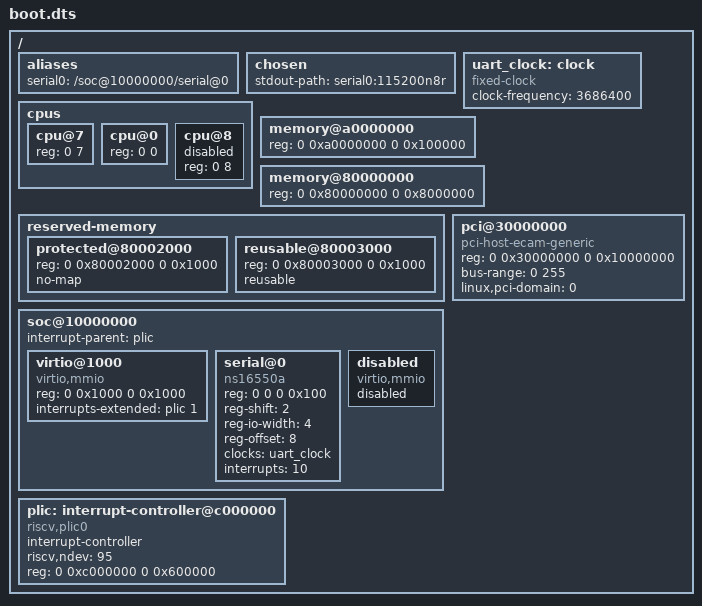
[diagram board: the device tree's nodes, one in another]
// SPDX-License-Identifier: MPL-2.0

/dts-v1/;
/memreserve/ 0x80000000 0x2000;

/ {
    #address-cells = <2>;
    #size-cells = <2>;

    aliases { serial0 = "/soc@10000000/serial@0"; };
    chosen { stdout-path = "serial0:115200n8r"; };
    uart_clock: clock { compatible = "fixed-clock"; #clock-cells = <0>; clock-frequency = <3686400>; };
    cpus {
        #address-cells = <2>;
        #size-cells = <0>;
        cpu@7 { device_type = "cpu"; reg = <0 7>; };
        cpu@0 { device_type = "cpu"; reg = <0 0>; };
        cpu@8 { device_type = "cpu"; reg = <0 8>; status = "disabled"; };
    };
    memory@a0000000 {
        device_type = "memory";
        reg = <0 0xa0000000 0 0x100000>;
    };
    memory@80000000 {
        device_type = "memory";
        reg = <0 0x80000000 0 0x8000000>;
    };
    reserved-memory {
        #address-cells = <2>;
        #size-cells = <2>;
        ranges;
        protected@80002000 { reg = <0 0x80002000 0 0x1000>; no-map; };
        reusable@80003000 { reg = <0 0x80003000 0 0x1000>; reusable; };
    };
    soc@10000000 {
        #address-cells = <2>;
        #size-cells = <2>;
        ranges = <0 0 0 0x10000000 0 0x1000000>;
        interrupt-parent = <&plic>;
        virtio@1000 {
            compatible = "virtio,mmio";
            reg = <0 0x1000 0 0x1000>;
            interrupts-extended = <&plic 1>;
        };
        serial@0 {
            compatible = "ns16550a";
            reg = <0 0 0 0x100>;
            reg-shift = <2>;
            reg-io-width = <4>;
            reg-offset = <8>;
            clocks = <&uart_clock>;
            interrupts = <10>;
        };
        disabled {
            compatible = "virtio,mmio";
            status = "disabled";
        };
    };
    pci@30000000 {
        compatible = "pci-host-ecam-generic";
        device_type = "pci";
        #address-cells = <3>;
        #size-cells = <2>;
        reg = <0 0x30000000 0 0x10000000>;
        bus-range = <0 255>;
        linux,pci-domain = <0>;
        ranges = <0x1000000 0 0 0 0x3000000 0 0x10000>,
                 <0x2000000 0 0x40000000 0 0x40000000 0 0x40000000>;
    };
    plic: interrupt-controller@c000000 {
        compatible = "riscv,plic0";
        interrupt-controller;
        #address-cells = <0>;
        #interrupt-cells = <1>;
        riscv,ndev = <95>;
        reg = <0 0xc000000 0 0x600000>;
    };
};
